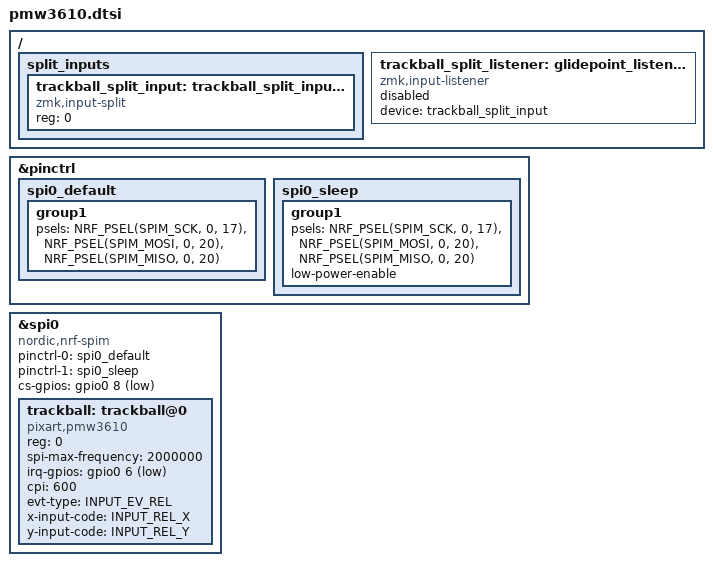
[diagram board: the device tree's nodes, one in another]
/* 
    For the peripheral side that has SPI pointing device with it.
    What's here: pinctrl & input split device for right & dongle side.

    The input listener that is used by the central side is added here but disabled by default.
    This is so that keymaps (which are included for both central and peripheral builds) can reference the listener to add input processors without failing with an undefined reference error.
    About input split device: https://zmk.dev/docs/development/hardware-integration/pointing#shared-configuration-1
*/

&pinctrl {
    spi0_default: spi0_default {
        group1 {
            /* main role: configure P0.17 as SPI clock, P0.20 as SPI MOSI, P0.20 as SPI MISO */
            psels = <NRF_PSEL(SPIM_SCK,  0, 17)>, // SCLK P0.17
                    <NRF_PSEL(SPIM_MOSI, 0, 20)>, // SDIO P0.20
                    <NRF_PSEL(SPIM_MISO, 0, 20)>;
        };
    };

    spi0_sleep: spi0_sleep {
        group1 {
            psels = <NRF_PSEL(SPIM_SCK,  0, 17)>, // SCLK P0.17
                    <NRF_PSEL(SPIM_MOSI, 0, 20)>, // SDIO P0.20
                    <NRF_PSEL(SPIM_MISO, 0, 20)>;
            low-power-enable;
        };
    };
};

#include <zephyr/dt-bindings/input/input-event-codes.h>

&spi0 { // input device node (SPI)
    status = "okay";
    compatible = "nordic,nrf-spim";
    pinctrl-0 = <&spi0_default>;
    pinctrl-1 = <&spi0_sleep>;
    pinctrl-names = "default", "sleep";
    cs-gpios = <&gpio0 8 GPIO_ACTIVE_LOW>; // nCS P0.08

    trackball: trackball@0 {
        status = "okay";
        compatible = "pixart,pmw3610";
        reg = <0>; // refers to the first SPI slave device
        spi-max-frequency = <2000000>;
        irq-gpios = <&gpio0 6 (GPIO_ACTIVE_LOW | GPIO_PULL_UP)>; // MOT P0.06
        cpi = <600>;
        evt-type = <INPUT_EV_REL>;
        x-input-code = <INPUT_REL_X>;
        y-input-code = <INPUT_REL_Y>;
        
        // force-awake will cause warping and cursor jumping. Don't recommend now.
    };
};

/ {
    split_inputs { // split input device
        #address-cells = <1>;
        #size-cells = <0>;

        trackball_split_input: trackball_split_input@0 { // trackball's split input device
            compatible = "zmk,input-split";
            reg = <0>;
        };
    };

    trackball_split_listener: glidepoint_listener { // listener for split input device
        compatible = "zmk,input-listener";
        status = "disabled"; // disable for .keymap to add input processors without undefined reference error
        device = <&trackball_split_input>;
    };
};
